# S32K312_M7 register map
Vendor: NXP Semiconductors; File version: 1.4
CPU: CM7 r0p1, little endian, MPU, FPU, VTOR, 4 interrupt priority bits
Registers are 32-bit, read-write, reset 0x0 unless marked. A register's access mark holds for its fields unless they carry their own. Offsets are from the block's base; [hi:lo] are bit positions; {n}, {i} and the like mark numbered series; 'fields as' and 'values as' point back to an identical list.

## I3C
Base 0x400C0000
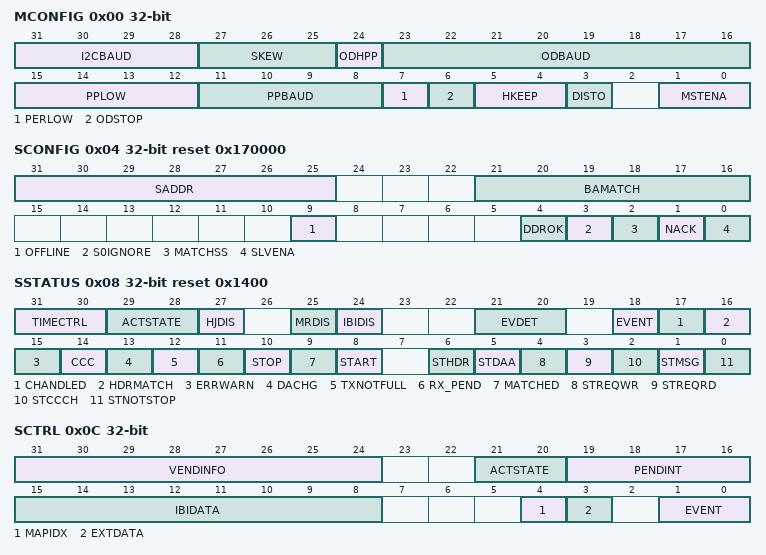
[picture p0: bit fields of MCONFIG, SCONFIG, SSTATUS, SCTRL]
0x00 MCONFIG — Master Configuration
  [31:28] I2CBAUD — I2C Baud Rate
  [27:25] SKEW
  [24] ODHPP — Open Drain High Push-Pull
  [23:16] ODBAUD — Open Drain Baud Rate
  [15:12] PPLOW — Push-Pull Low
  [11:8] PPBAUD — Push-Pull Baud Rate
  [7] PERLOW — Period low
  [6] ODSTOP — Open Drain Stop
  [5:4] HKEEP — High-Keeper
    0=NONE; 1=WIRED_IN; 2=PASSIVE_SDA; 3=PASSIVE_ON_SDA_SCL
  [3] DISTO — Disable Timeout
  [1:0] MSTENA — Master Enable
    0=MASTER_OFF; 1=MASTER_ON; 2=MASTER_CAPABLE
0x04 SCONFIG reset 0x170000 — Slave Configuration
  [31:25] SADDR — Static Address
  [21:16] BAMATCH — Bus Available Match
  [9] OFFLINE
  [4] DDROK — Double Data Rate OK
  [3] S0IGNORE — S0/S1 Errors Ignore
  [2] MATCHSS — Match START or STOP
  [1] NACK — Not Acknowledge
  [0] SLVENA — Slave Enable
0x08 SSTATUS reset 0x1400 — Slave Status
  [31:30] TIMECTRL ro — Time Control
    0=NO_TIME_CONTROL; 1=SYNC (SYNC_MODE); 2=ASYNC_MODE; 3=BOTHSYNCASYNC
  [29:28] ACTSTATE ro — Activity State from Common Command Codes (CCC)
    0=NO_LATENCY; 1=LATENCY_1MS; 2=LATENCY_100MS; 3=LATENCY_10S
  [27] HJDIS ro — Hot-Join Is Disabled
  [25] MRDIS ro — Master Requests Are Disabled
  [24] IBIDIS ro — In-Band Interrupts Are Disabled
  [21:20] EVDET ro — Event Details
    0=NONE; 1=NO_REQUEST; 2=NACKED; 3=ACKED
  [18] EVENT write-1-clears
  [17] CHANDLED write-1-clears — Common Command Code Handled
  [16] HDRMATCH write-1-clears — High Data Rate Command Match
  [15] ERRWARN ro — Error Warning
  [14] CCC write-1-clears — Common Command Code
  [13] DACHG write-1-clears — Dynamic Address Change
  [12] TXNOTFULL ro — Transmit Buffer Is Not Full
  [11] RX_PEND ro — Received Message Pending
  [10] STOP write-1-clears
  [9] MATCHED write-1-clears
  [8] START write-1-clears
  [6] STHDR ro — Status High Data Rate
  [5] STDAA ro — Status Dynamic Address Assignment
  [4] STREQWR ro — Status Request Write
  [3] STREQRD ro — Status Request Read
  [2] STCCCH ro — Status Common Command Code Handler
  [1] STMSG ro — Status message
  [0] STNOTSTOP ro — Status Not Stop
0x0C SCTRL — Slave Control
  [31:24] VENDINFO — Vendor Information
  [21:20] ACTSTATE — Activity State (of slave)
  [19:16] PENDINT — Pending Interrupt
  [15:8] IBIDATA — In-Band Interrupt Data
  [4] MAPIDX — Map Index
  [3] EXTDATA — Extended Data
  [1:0] EVENT
    0=NORMAL_MODE; 1=IBI; 2=MASTER_REQUEST; 3=HOT_JOIN_REQUEST
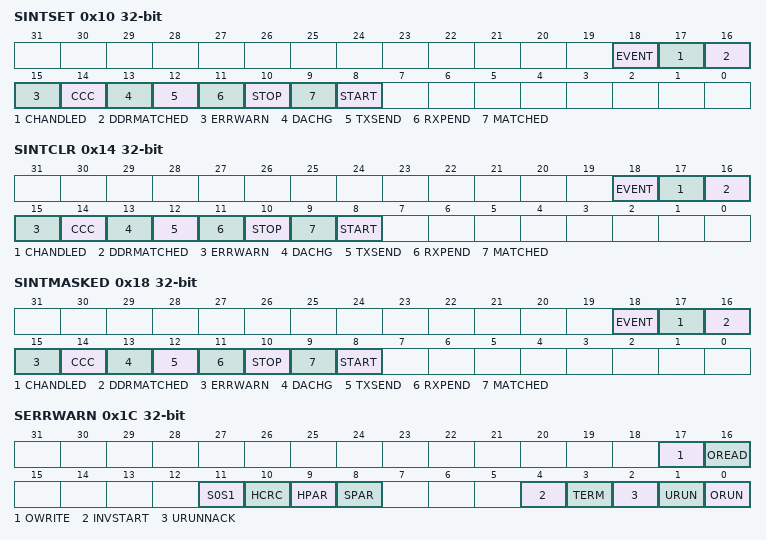
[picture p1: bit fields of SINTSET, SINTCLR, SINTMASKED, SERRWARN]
0x10 SINTSET write-1-sets — Slave Interrupt Set
  [18] EVENT write-1-sets — Event Interrupt Enable
  [17] CHANDLED write-1-sets — Common Command Code (CCC) (that was handled by I3C module) Interrupt Enable
  [16] DDRMATCHED write-1-sets — Double Data Rate Interrupt Enable
  [15] ERRWARN write-1-sets — Error/Warning Interrupt Enable
  [14] CCC write-1-sets — Common Command Code (CCC) (that was not handled by I3C module) Interrupt Enable
  [13] DACHG write-1-sets — Dynamic Address Change Interrupt Enable
  [12] TXSEND write-1-sets — Transmit Interrupt Enable
  [11] RXPEND write-1-sets — Receive Interrupt Enable
  [10] STOP write-1-sets — Stop Interrupt Enable
  [9] MATCHED write-1-sets — Match interrupt enable
  [8] START write-1-sets — Start Interrupt Enable
0x14 SINTCLR reset not defined write-1-clears — Slave Interrupt Clear
  [18] EVENT write-1-clears — EVENT Interrupt Enable Clear
  [17] CHANDLED write-1-clears — CHANDLED Interrupt Enable Clear
  [16] DDRMATCHED write-1-clears — DDRMATCHED Interrupt Enable Clear
  [15] ERRWARN write-1-clears — ERRWARN Interrupt Enable Clear
  [14] CCC write-1-clears — CCC Interrupt Enable Clear
  [13] DACHG write-1-clears — DACHG Interrupt Enable Clear
  [12] TXSEND write-1-clears — TXSEND Interrupt Enable Clear
  [11] RXPEND write-1-clears — RXPEND Interrupt Enable Clear
  [10] STOP write-1-clears — STOP Interrupt Enable Clear
  [9] MATCHED write-1-clears — MATCHED Interrupt Enable Clear
  [8] START write-1-clears — START Interrupt Enable Clear
0x18 SINTMASKED ro — Slave Interrupt Mask
  [18] EVENT — EVENT Interrupt Mask
  [17] CHANDLED — CHANDLED Interrupt Mask
  [16] DDRMATCHED — DDRMATCHED Interrupt Mask
  [15] ERRWARN — ERRWARN Interrupt Mask
  [14] CCC — CCC Interrupt Mask
  [13] DACHG — DACHG Interrupt Mask
  [12] TXSEND — TXSEND Interrupt Mask
  [11] RXPEND — RXPEND Interrupt Mask
  [10] STOP — STOP Interrupt Mask
  [9] MATCHED — MATCHED Interrupt Mask
  [8] START — START interrupt mask
0x1C SERRWARN write-1-clears — Slave Errors and Warnings
  [17] OWRITE write-1-clears — Over-write Error
  [16] OREAD write-1-clears — Over-read Error
  [11] S0S1 write-1-clears — S0 or S1 Error
  [10] HCRC write-1-clears — HDR-DDR CRC Error
  [9] HPAR write-1-clears — HDR Parity Error
  [8] SPAR write-1-clears — SDR Parity Error
  [4] INVSTART write-1-clears — Invalid Start Error
  [3] TERM write-1-clears — Terminated Error
  [2] URUNNACK write-1-clears — Underrun and Not Acknowledged (NACKED) Error
  [1] URUN write-1-clears — Underrun Error
  [0] ORUN write-1-clears — Overrun Error
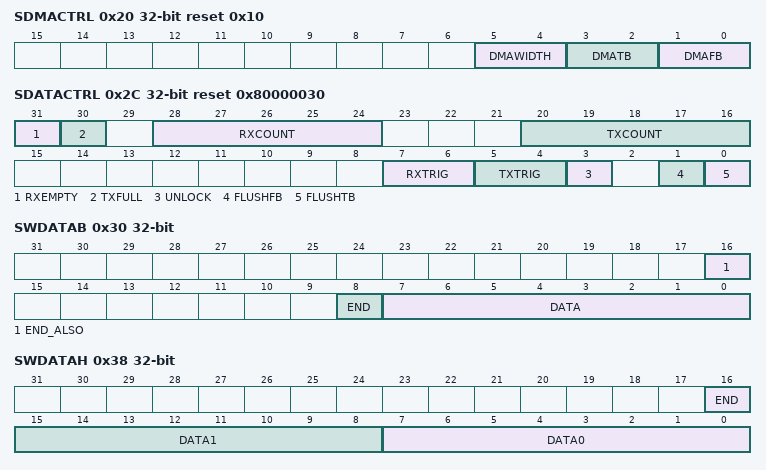
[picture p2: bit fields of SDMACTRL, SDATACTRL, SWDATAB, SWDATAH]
0x20 SDMACTRL reset 0x10 — Slave DMA Control
  [5:4] DMAWIDTH — Width of DMA Operations
    0=BYTE_0 (BYTE, Default = 1); 1=BYTE_1 (BYTE, Default = 1); 2=HALF_WORD
  [3:2] DMATB — DMA Write (To-bus) Trigger
    0=NOT_USED; 1=ENABLE_ONE_FRAME; 2=ENABLE
  [1:0] DMAFB — DMA Read (From-bus) Trigger
    0=NOT_USED (DMA not used); 1=ENABLE_ONE_FRAME (DMA is enabled for 1 frame); 2=ENABLE (DMA Enable)
0x2C SDATACTRL reset 0x80000030 — Slave Data Control
  [31] RXEMPTY ro — Rx Is Empty
    0=RXISNOTEMPTY; 1=RXISEMPTY
  [30] TXFULL ro — TX Is Full
    0=TXISNOTFULL; 1=TXISFULL
  [28:24] RXCOUNT ro — Count Of Bytes In RX
  [20:16] TXCOUNT ro — Count Of Bytes In TX
  [7:6] RXTRIG — Trigger Level For Rx FIFO Fullness
    0=TRIGGRNOTEMPTY (Trigger on not empty); 1=TRIGGRONEFOURTH (Trigger on or more full); 2=TRIGGRONEHALF (Trigger on .5 or more full); 3=TRIGGRTHREEFOURTHS (Trigger on 3/4 or more full)
  [5:4] TXTRIG — Trigger Level For Tx FIFO Emptiness
    0=TRIGGREMPTY (Trigger on empty); 1=TRIGGRONEFOURTH (Trigger on full or less); 2=TRIGGRONEHALF (Trigger on .5 full or less); 3=TRIGGRONELESS (Trigger on 1 less than full or less (Default))
  [3] UNLOCK wo
    0=DISABLED (RXTRIG and TXTRIG fields cannot be changed on a write.); 1=ENABLED (RXTRIG and TXTRIG fields can be changed on a write.)
  [1] FLUSHFB wo — Flushes The From-bus Buffer/FIFO
  [0] FLUSHTB wo — Flush The To-bus Buffer/FIFO
0x30 SWDATAB wo reset not defined — Slave Write Data Byte
  [16] END_ALSO, [8] END, [7:0] DATA
0x34 SWDATABE wo reset not defined — Slave Write Data Byte End
  [7:0] DATA
0x38 SWDATAH wo reset not defined — Slave Write Data Half-word
  [16] END — End of message
  [15:8] DATA1
  [7:0] DATA0
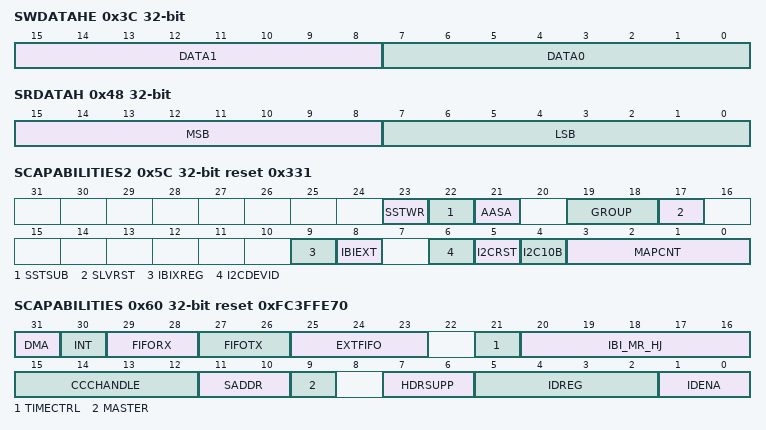
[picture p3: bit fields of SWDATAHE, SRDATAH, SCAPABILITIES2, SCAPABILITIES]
0x3C SWDATAHE wo reset not defined — Slave Write Data Half-word End
  [15:8] DATA1, [7:0] DATA0
0x40 SRDATAB ro — Slave Read Data Byte
  [7:0] DATA0
0x48 SRDATAH ro — Slave Read Data Half-word
  [15:8] MSB — The 2nd byte read from the slave.
  [7:0] LSB — The 1st byte read from the slave.
0x5C SCAPABILITIES2 ro reset 0x331 — Slave Capabilities 2
  [23] SSTWR — Slave-Slave(s)-Tunnel Write Capable
  [22] SSTSUB — Slave-Slave(s)-Tunnel Subscriber Capable
  [21] AASA — Supports SETAASA
  [19:18] GROUP
    0=NOTSUPPORTED (Does not supports v1.1 Group addressing); 1=ONE (Supports one group); 2=TWO (Supports two groups); 3=THREE (Supports three groups)
  [17] SLVRST — Slave Reset
    0=DISABLE (Does not support Slave Reset); 1=ENABLE (Supports Slave Reset)
  [9] IBIXREG — In-Band Interrupt Extended Register
    0=DISABLE (Does not support IBIXREG); 1=ENABLE (Supports IBIXREG)
  [8] IBIEXT — In-Band Interrupt EXTDATA
    0=DISABLE (Does not support IBIEXT); 1=ENABLE (Supports IBIEXT)
  [6] I2CDEVID — I2C Device ID
    0=DISABLE (Does not support I2CDEVID); 1=ENABLE (Supports I2CDEVID)
  [5] I2CRST — I2C SW Reset
    0=DISABLE (Does not support I2CRST); 1=ENABLE (Supports I2CRST)
  [4] I2C10B — I2C 10-bit Address
    0=DISABLE (Does not support I2C10B); 1=ENABLE (Supports I2C10B)
  [3:0] MAPCNT — Map Count
0x60 SCAPABILITIES ro reset 0xFC3FFE70 — Slave Capabilities
  [31] DMA — Direct Memory Access
    0=DMANO (DMA is not supported); 1=DMAYES (DMA is supported)
  [30] INT — Interrupts
    0=INTERRUPTSNO (Interrupts are not supported); 1=INTERRUPTSYES (Interrupts are supported)
  [29:28] FIFORX — FIFO Receive
    0=FIFO_2BYTE; 1=FIFO_4BYTE; 2=FIFO_8BYTE; 3=FIFO_16BYTE
  [27:26] FIFOTX — FIFO Transmit
    0=FIFO_2BYTE; 1=FIFO_4BYTE (FIFO_4BYTE: 4-byte Tx FIFO); 2=FIFO_8BYTE (FIFO_8BYTE: 8-byte Tx FIFO); 3=FIFO_16BYTE (FIFO_16BYTE: 16-byte Tx FIFO or larger)
  [25:23] EXTFIFO — External FIFO
    0=NO_EXT_FIFO; 1=STD_EXT_FIFO; 2=REQUEST_EXT_FIFO
  [21] TIMECTRL — Time Control
    0=NO_TIME_CONTROL_TYPE; 1=ATLEAST1_TIME_CONTROL
  [20:16] IBI_MR_HJ — In-Band Interrupts, Master Requests, Hot-Join Events
  [15:12] CCCHANDLE — Common Command Codes Handling
  [11:10] SADDR — Static Address
    0=NO_STATIC; 1=STATIC; 2=HW_CONTROL; 3=CONFIG
  [9] MASTER
    0=MASTERNOTSUPPORTED; 1=MASTERSUPPORTED
  [7:6] HDRSUPP — High Data Rate Support
  [5:2] IDREG — ID Register
  [1:0] IDENA — ID 48b Handler
    0=APPLICATION; 1=HW; 2=HW_BUT; 3=PARTNO
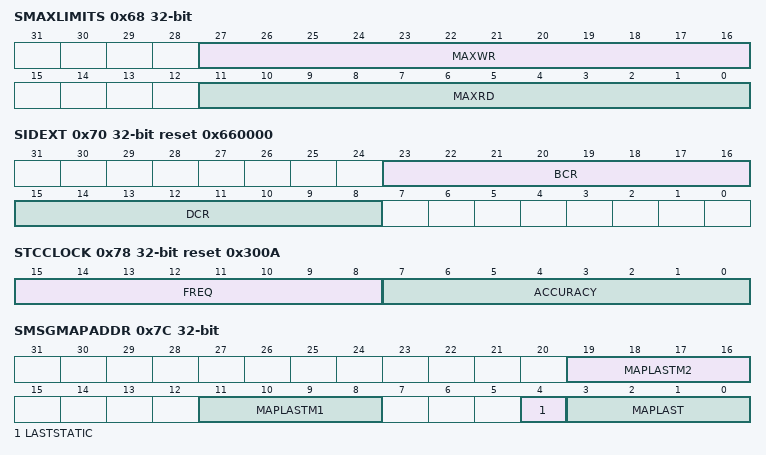
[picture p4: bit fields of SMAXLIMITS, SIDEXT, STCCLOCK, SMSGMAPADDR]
0x68 SMAXLIMITS — Slave Maximum Limits
  [27:16] MAXWR — Maximum Write Length
  [11:0] MAXRD — Maximum Read Length
0x6C SIDPARTNO — Slave ID Part Number
  [31:0] PARTNO — Part number
0x70 SIDEXT reset 0x660000 — Slave ID Extension
  [23:16] BCR — Bus Characteristics Register
  [15:8] DCR — Device Characteristic Register
0x74 SVENDORID reset 0x11B — Slave Vendor ID
  [14:0] VID — Vendor ID
0x78 STCCLOCK reset 0x300A — Slave Time Control Clock
  [15:8] FREQ — Clock Frequency
  [7:0] ACCURACY — Clock Accuracy
0x7C SMSGMAPADDR ro — Slave Message Map Address
  [19:16] MAPLASTM2 — Matched Previous Index 2
  [11:8] MAPLASTM1 — Matched Previous Address Index 1
  [4] LASTSTATIC — Last Static Address Matched
  [3:0] MAPLAST — Matched Address Index
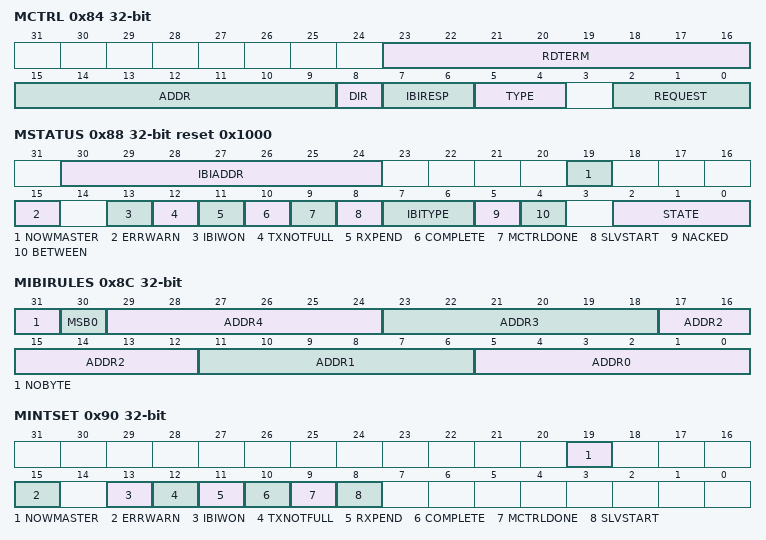
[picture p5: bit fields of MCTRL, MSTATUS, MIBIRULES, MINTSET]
0x84 MCTRL — Master Control
  [23:16] RDTERM — Read Terminate
  [15:9] ADDR — Address
  [8] DIR — Direction
    0=DIRWRITE (DIRWRITE: Write); 1=DIRREAD (DIRREAD: Read)
  [7:6] IBIRESP — In-Band Interrupt Response
    0=ACK; 1=NACK; 2=ACK_WITH_MANDATORY; 3=MANUAL
  [5:4] TYPE — Bus Type with EmitStartAddr
    0=I3C; 1=I2C; 2=DDR
  [2:0] REQUEST
    0=NONE; 1=EMITSTARTADDR; 2=EMITSTOP; 3=IBIACKNACK; 4=PROCESSDAA; 6=FORCEEXIT (Force Exit and Slave Reset); 7=AUTOIBI
0x88 MSTATUS reset 0x1000 — Master Status
  [30:24] IBIADDR ro — IBI Address
  [19] NOWMASTER write-1-clears — Now Master (now this module is a master)
  [15] ERRWARN ro — Error Or Warning
  [13] IBIWON write-1-clears — In-Band Interrupt (IBI) Won
  [12] TXNOTFULL ro — TX buffer/FIFO not yet full
  [11] RXPEND ro
  [10] COMPLETE write-1-clears
  [9] MCTRLDONE write-1-clears — Master Control Done
  [8] SLVSTART write-1-clears — Slave Start
  [7:6] IBITYPE ro — In-Band Interrupt (IBI) Type
    0=NONE; 1=IBI; 2=MR; 3=HJ
  [5] NACKED ro — Not Acknowledged
  [4] BETWEEN ro
    0=INACTIVE; 1=ACTIVE
  [2:0] STATE ro — State Of The Master
    0=IDLE (IDLE: the bus has Stopped.); 1=SLVREQ; 2=MSGSDR; 3=NORMACT; 4=DDR (MSGDDR); 5=DAA; 6=IBIACK; 7=IBIRCV
0x8C MIBIRULES — Master In-band Interrupt Registry and Rules
  [31] NOBYTE — No IBI byte
  [30] MSB0 — Set Most Significant address Bit to 0
  [6n+5:6n] ADDR{n} (n=0..4)
0x90 MINTSET write-1-sets — Master Interrupt Set
  [19] NOWMASTER write-1-sets — Now Master (now this I3C module is a master) Interrupt Enable
  [15] ERRWARN write-1-sets — Error or Warning (ERRWARN) Interrupt Enable
  [13] IBIWON write-1-sets — In-Band Interrupt (IBI) Won Interrupt Enable
  [12] TXNOTFULL write-1-sets — TX buffer/FIFO is not full interrupt enable
  [11] RXPEND write-1-sets — Rx Pending Interrupt Enable
  [10] COMPLETE write-1-sets — Completed Message Interrupt Enable
  [9] MCTRLDONE write-1-sets — Master Control Done Interrupt Enable
  [8] SLVSTART write-1-sets — Slave Start Interrupt Enable
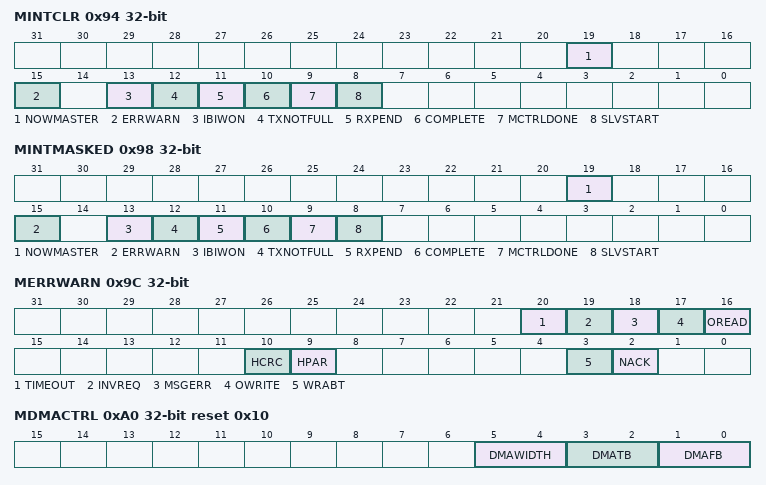
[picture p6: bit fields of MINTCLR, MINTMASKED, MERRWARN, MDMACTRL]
0x94 MINTCLR reset not defined write-1-clears — Master Interrupt Clear
  [19] NOWMASTER write-1-clears — NOWMASTER Interrupt Enable Clear
  [15] ERRWARN write-1-clears — ERRWARN Interrupt Enable Clear
  [13] IBIWON write-1-clears — IBIWON Interrupt Enable Clear
  [12] TXNOTFULL write-1-clears — TXNOTFULL Interrupt Enable Clear
  [11] RXPEND write-1-clears — RXPEND Interrupt Enable Clear
  [10] COMPLETE write-1-clears — COMPLETE Interrupt Enable Clear
  [9] MCTRLDONE write-1-clears — MCTRLDONE Interrupt Enable Clear
  [8] SLVSTART write-1-clears — SLVSTART Interrupt Enable Clear
0x98 MINTMASKED ro — Master Interrupt Mask
  [19] NOWMASTER — NOWMASTER Interrupt Mask
  [15] ERRWARN — ERRWARN Interrupt Mask
  [13] IBIWON — IBIWON Interrupt Mask
  [12] TXNOTFULL — TXNOTFULL Interrupt Mask
  [11] RXPEND — RXPEND Interrupt Mask
  [10] COMPLETE — COMPLETE Interrupt Mask
  [9] MCTRLDONE — MCTRLDONE Interrupt Mask
  [8] SLVSTART — SLVSTART Interrupt Mask
0x9C MERRWARN write-1-clears — Master Errors and Warnings
  [20] TIMEOUT write-1-clears — Timeout Error
  [19] INVREQ write-1-clears — Invalid Request Error
  [18] MSGERR write-1-clears — Message Error
  [17] OWRITE write-1-clears — Over-write Error
  [16] OREAD write-1-clears — Over-read Error
  [10] HCRC write-1-clears — High Data Rate CRC Error
  [9] HPAR write-1-clears — High Data Rate Parity
  [3] WRABT write-1-clears — Write Abort Error
  [2] NACK write-1-clears — Not Acknowledge Error
0xA0 MDMACTRL reset 0x10 — Master DMA Control
  [5:4] DMAWIDTH
    0=BYTE_0; 1=BYTE_1; 2=HALF_WORD
  [3:2] DMATB — DMA To Bus
    0=NOT_USED; 1=ENABLE_ONE_FRAME; 2=ENABLE
  [1:0] DMAFB — DMA From Bus
    0=NOT_USED; 1=ENABLE_ONE_FRAME; 2=ENABLE
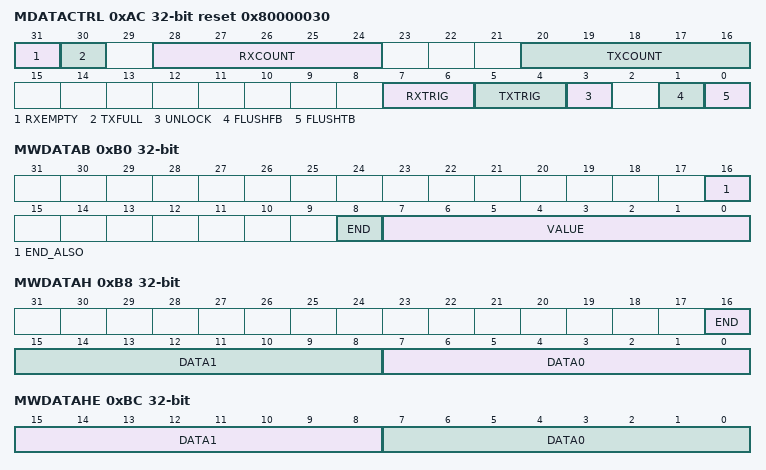
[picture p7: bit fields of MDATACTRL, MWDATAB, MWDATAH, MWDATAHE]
0xAC MDATACTRL reset 0x80000030 — Master Data Control
  [31] RXEMPTY ro — Receive Is Empty.
    0=NOT_EMPTY (Rx is not yet empty.); 1=EMPTY (Rx is empty.)
  [30] TXFULL ro — Transmit Is Full.
    0=NOT_FULL (Tx is not yet full.); 1=FULL (Tx is full.)
  [28:24] RXCOUNT ro — Receive Byte Count
  [20:16] TXCOUNT ro — Transmit Byte Count
  [7:6] RXTRIG — Receive Trigger Level
    0=NOT_EMPTY (Trigger on not empty); 1=QUARTER_OR_MORE (Trigger on 1/4 full or more); 2=HALF_OR_MORE (Trigger on 1/2 full or more); 3=THREE_QUARTER_OR_MORE (Trigger on 3/4 full or more)
  [5:4] TXTRIG — Transmit Trigger Level
    0=EMPTY (Trigger on empty); 1=QUARTER_OR_LESS (Trigger on 1/4 full or less); 2=HALF_OR_LESS (Trigger on 1/2 full or less); 3=FULL_OR_LESS (Default. Trigger on 1 less than full or less)
  [3] UNLOCK wo
    values as SDATACTRL.UNLOCK
  [1] FLUSHFB wo — Flush From-bus Buffer/FIFO
  [0] FLUSHTB wo — Flush To-bus Buffer/FIFO
0xB0 MWDATAB wo reset not defined — Master Write Data Byte
  [16] END_ALSO — End of Message Also
  [8] END — End of Message
  [7:0] VALUE — Data Byte
0xB4 MWDATABE wo reset not defined — Master Write Data Byte End
  [7:0] VALUE — Data
0xB8 MWDATAH wo reset not defined — Master Write Data Half-word
  [16] END — End of message
  [15:8] DATA1 — Data Byte 1
  [7:0] DATA0 — Data Byte 0
0xBC MWDATAHE wo reset not defined — Master Write Data Byte End
  [15:8] DATA1 — Data Byte 1
  [7:0] DATA0 — ata Byte 0
0xC0 MRDATAB ro — Master Read Data Byte
  [7:0] VALUE
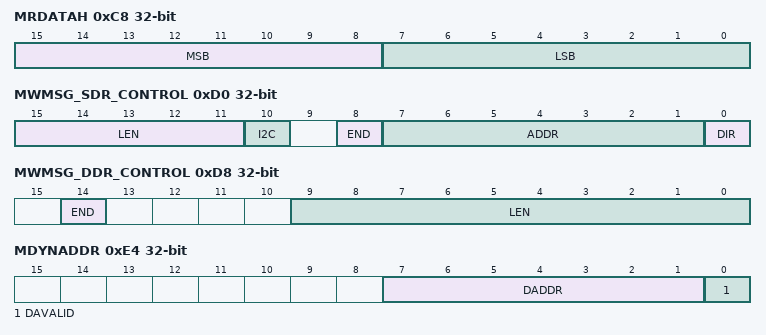
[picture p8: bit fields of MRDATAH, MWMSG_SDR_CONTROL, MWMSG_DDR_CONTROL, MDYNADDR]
0xC8 MRDATAH ro — Master Read Data Half-word
  [15:8] MSB, [7:0] LSB
0xCC MWDATAB1 wo — Byte-only Write Byte Data (to bus)
  [7:0] VALUE
0xD0 MWMSG_SDR_CONTROL wo reset not defined (MWMSG_SDR view) — Master Write Message in SDR mode
  [15:11] LEN — Length
  [10] I2C
    0=I3CMESSAGE; 1=I2CMESSAGE
  [8] END — End of SDR Message
  [7:1] ADDR — Address
  [0] DIR — Direction
    0=WRITE; 1=READ
0xD0 MWMSG_SDR_DATA wo (MWMSG_SDR view) — Master Write Message Data in SDR mode
  [15:0] DATA16B — Data
0xD4 MRMSG_SDR ro — Master Read Message in SDR mode
  [15:0] DATA
0xD8 MWMSG_DDR_CONTROL wo reset not defined (MWMSG_DDR view) — Master Write Message in DDR mode
  [14] END — End of message
  [9:0] LEN — Length of Message
0xD8 MWMSG_DDR_DATA wo (MWMSG_DDR view) — Master Write Message Data in DDR mode
  [15:0] DATA16B — Data
0xDC MRMSG_DDR ro — Master Read Message in DDR mode
  [15:0] DATA
0xE4 MDYNADDR — Master Dynamic Address
  [7:1] DADDR — Dynamic address
  [0] DAVALID — Dynamic address valid
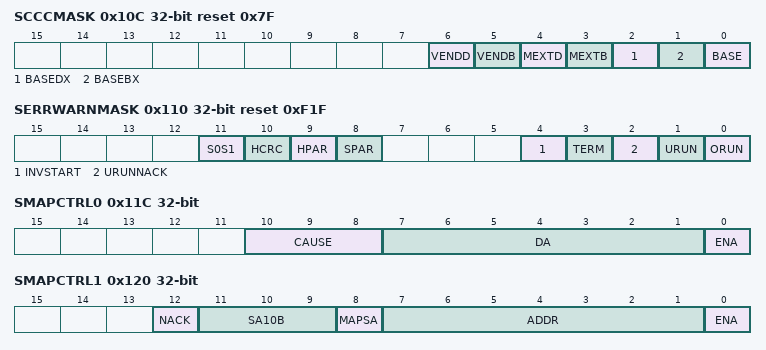
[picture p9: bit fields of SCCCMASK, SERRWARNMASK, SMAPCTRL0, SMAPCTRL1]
0x10C SCCCMASK reset 0x7F — CCC Mask for Unhandled CCCs
  [all] fields
    0=DISABLE (Unhandled CCC in given range suppressed); 1=ENABLE (Unhandled CCC in given range passed to application)
  [6] VENDD
  [5] VENDB
  [4] MEXTD
  [3] MEXTB
  [2] BASEDX
  [1] BASEBX
  [0] BASE
0x110 SERRWARNMASK reset 0xF1F — Slave Errors and Warnings Mask
  [11] S0S1 — S0S1 mask
  [10] HCRC — HCRC mask
  [9] HPAR — HPAR mask
  [8] SPAR — SPAR mask
  [4] INVSTART — INVSTART mask
  [3] TERM — TERM mask
  [2] URUNNACK — URUNNACK mask
  [1] URUN — URUN mask
  [0] ORUN — ORUN mask
0x11C SMAPCTRL0 ro — Map Feature Control 0
  [10:8] CAUSE
  [7:1] DA — Dynamic Address
  [0] ENA — Enable
0x120 SMAPCTRL1 — Map Feature Control 1
  [12] NACK — No Acknowledge
  [11:9] SA10B — Static Address 10-bit Extension
  [8] MAPSA — MAP Static Address
    0=DISABLE (I3C Dynamic Address); 1=ENABLE (Static Address (I2C style))
  [7:1] ADDR — Address
  [0] ENA — Enable
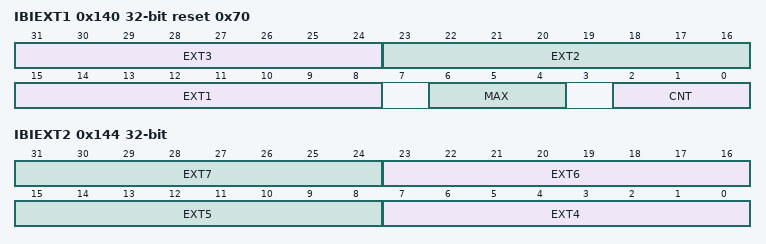
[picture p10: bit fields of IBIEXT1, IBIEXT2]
0x140 IBIEXT1 reset 0x70 — Extended IBI Data 1
  [31:24] EXT3 — Extra byte 3
  [23:16] EXT2 — Extra byte 2
  [15:8] EXT1 — Extra byte 1
  [6:4] MAX ro — Maximum
  [2:0] CNT — Count
0x144 IBIEXT2 — Extended IBI Data 2
  [8n-25:8n-32] EXT{n} (n=4..7) — Extra byte {n}
